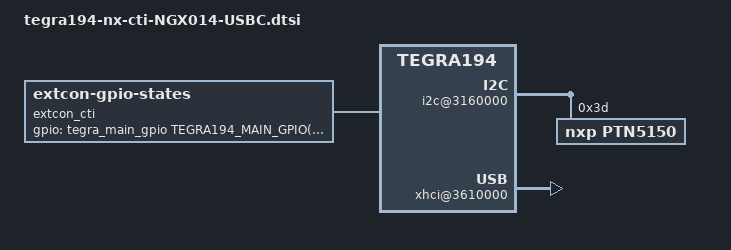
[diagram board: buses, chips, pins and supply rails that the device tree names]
/*
    Adds support for the Alternative USB-C Controllers used 
    on the NGX014 version of the Connect Tech Quark Carrier.
    This can be used safely with standard NGX004 boards. 
*/

/{

    i2c@3160000{
        status = "okay";
                ptn5150@3d{
                    compatible = "nxp,ptn5150";
                    reg = <0x3d>;
                    cti,optional;
                    regulator-init-microamp = <1500000>;    //1.5Amps
                    status = "okay";
                };
        };

        extcon_cti: extcon_cti {
                #extcon-cells = <1>;
                compatible = "extcon-gpio-states";
                extcon-gpio,name = "VBUS_ID";

                //VBusDetect and OTG ID
                gpios = <&tegra_main_gpio TEGRA194_MAIN_GPIO(Z, 1) 0
                                 &tegra_main_gpio TEGRA194_MAIN_GPIO(Q, 1) 0>;

                extcon-gpio,cable-states = <0x0 EXTCON_USB_HOST
                                                                        0x1 EXTCON_USB_HOST
                                                                        0x2 EXTCON_NONE
                                                                        0x3 EXTCON_USB>;
                extcon-gpio,wait-for-gpio-scan = <0>;
                extcon-gpio,out-cable-names = <EXTCON_USB EXTCON_USB_HOST EXTCON_NONE>;
                status = "okay";
        };
    xhci@3610000{
        extcon-cable-names = "id";
        extcon-cables = <&extcon_cti 1>;
        status = "okay";
                phys = <&{/xusb_padctl@3520000/pads/usb2/lanes/usb2-0}>,
                        <&{/xusb_padctl@3520000/pads/usb2/lanes/usb2-1}>,
                        <&{/xusb_padctl@3520000/pads/usb2/lanes/usb2-2}>,
                        <&{/xusb_padctl@3520000/pads/usb3/lanes/usb3-2}>;
                phy-names = "usb2-0", "usb2-1", "usb2-2", "usb3-2";
    };


};

